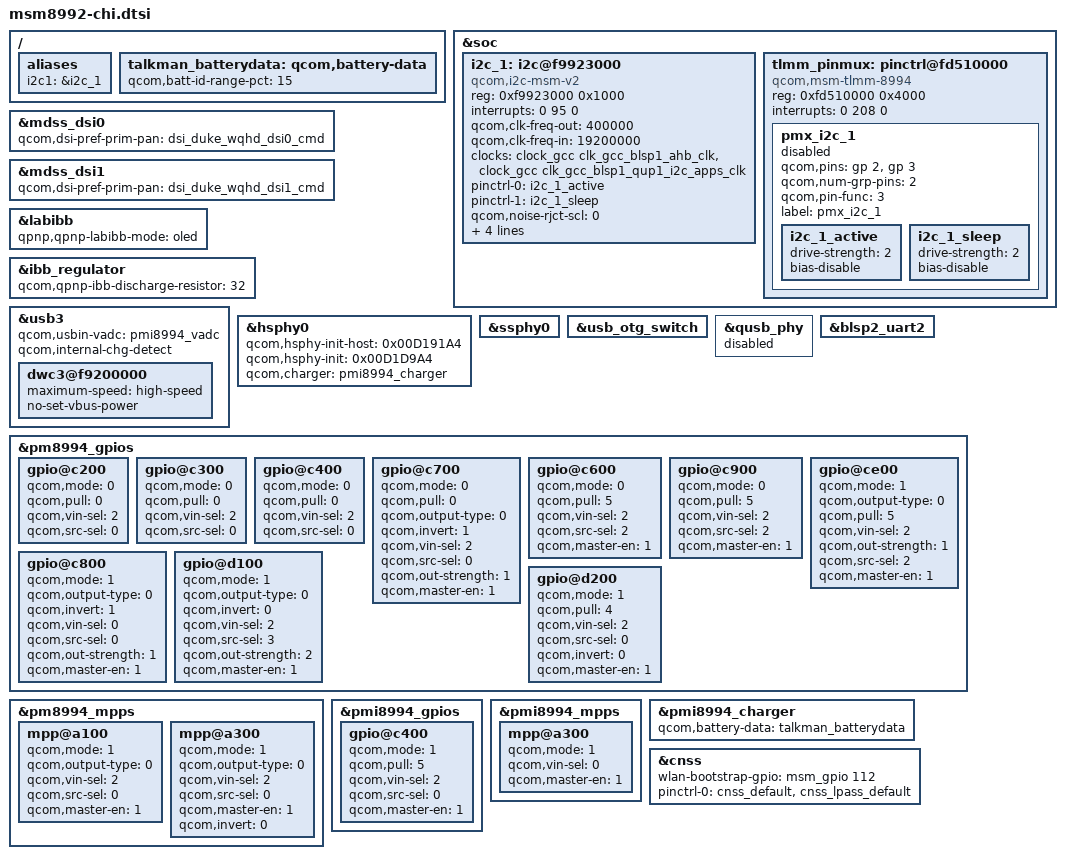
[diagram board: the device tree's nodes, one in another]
/* Copyright (c) 2014-2015, The Linux Foundation. All rights reserved.
 *
 * This program is free software; you can redistribute it and/or modify
 * it under the terms of the GNU General Public License version 2 and
 * only version 2 as published by the Free Software Foundation.
 *
 * This program is distributed in the hope that it will be useful,
 * but WITHOUT ANY WARRANTY; without even the implied warranty of
 * MERCHANTABILITY or FITNESS FOR A PARTICULAR PURPOSE.  See the
 * GNU General Public License for more details.
 */

 #include "../qcom/msm8992-pinctrl.dtsi"
 #include "common/pinctrl.dtsi"
 #include "../qcom/msm8992-camera-sensor-mtp.dtsi"
 #include "common/regulator.dtsi"
 #include "common/connectivity.dtsi"
 #include "common/sdhc.dtsi"
 #include "common/haptics.dtsi"
 #include "common/touch.dtsi"
 #include "common/silabs.dtsi"
 #include "common/sidekeys.dtsi"
 #include "common/audio.dtsi"
 #include "common/adc.dtsi"
 #include "common/charger.dtsi"
 #include "common/hdmi.dtsi"
 #include "common/mdss.dtsi"
 #include "common/reserved-memory.dtsi"
 #include "common/nfc.dtsi"
 #include "common/ice40.dtsi"
 
 / {
	 aliases {
		 i2c1 = &i2c_1;
	 };
 };
 
 &soc {
		 i2c_1: i2c@f9923000 {
		 compatible = "qcom,i2c-msm-v2";
		 #address-cells = <1>;
		 #size-cells = <0>;
		 reg-names = "qup_phys_addr";
		 reg = <0xf9923000 0x1000>;
		 interrupt-names = "qup_irq";
		 interrupts = <0 95 0>;
		 qcom,clk-freq-out = <400000>;
		 qcom,clk-freq-in  = <19200000>;
		 clock-names = "iface_clk", "core_clk";
		 clocks = <&clock_gcc clk_gcc_blsp1_ahb_clk>,
			  <&clock_gcc clk_gcc_blsp1_qup1_i2c_apps_clk>;
 
		 pinctrl-names = "i2c_active", "i2c_sleep";
		 pinctrl-0 = <&i2c_1_active>;
		 pinctrl-1 = <&i2c_1_sleep>;
		 qcom,noise-rjct-scl = <0>;
		 qcom,noise-rjct-sda = <0>;
		 qcom,master-id = <86>;
		 dmas = <&dma_blsp1 10 64 0x20000020 0x20>,
			 <&dma_blsp1 11 32 0x20000020 0x20>;
		 dma-names = "tx", "rx";
 
	 };
 
 
		 tlmm_pinmux: pinctrl@fd510000 {
		 compatible = "qcom,msm-tlmm-8994", "qcom,msm-tlmm-8974";
		 reg = <0xfd510000 0x4000>;
		 interrupts = <0 208 0>;
 
			 pmx_i2c_1 {
			 qcom,pins = <&gp 2>, <&gp 3>; /* SDA, SCL */
			 qcom,num-grp-pins = <2>;
			 qcom,pin-func = <3>;
			 label = "pmx_i2c_1";
 
			 status = "disabled";
 
			 i2c_1_active: i2c_1_active {
				 drive-strength = <2>;
				 bias-disable;
			 };
 
			 i2c_1_sleep: i2c_1_sleep {
				 drive-strength = <2>;
				 bias-disable;
			 };
		 };
	 };
 
 };
 
 #include "panels/dsi-panel-duke-wqhd-dualdsi-cmd.dtsi"
 
 //Sergej panel has more timout for cmds -- fixing a green line on screen when powering off bug
 //Won't use it though, will just have to adjust the timing later down the line 
&mdss_dsi0 {
	 qcom,dsi-pref-prim-pan = <&dsi_duke_wqhd_dsi0_cmd>;
 };
 
 &mdss_dsi1 {
	 qcom,dsi-pref-prim-pan = <&dsi_duke_wqhd_dsi1_cmd>;
 };
 
 &labibb {
	 status = "ok";
	 qpnp,qpnp-labibb-mode = "oled";
 };
 
 &ibb_regulator {
	 qcom,qpnp-ibb-discharge-resistor = <32>;
 };
 
 &usb3 {
	 status = "ok";
	 qcom,usbin-vadc = <&pmi8994_vadc>;
	 qcom,internal-chg-detect;
 
	 dwc3@f9200000 {
		 maximum-speed = "high-speed";
		 no-set-vbus-power;
	 };
 };
 
 &hsphy0 {
	 status = "ok";
	 qcom,hsphy-init-host = <0x00D191A4>;
	 qcom,hsphy-init = <0x00D1D9A4>;
	 qcom,charger = <&pmi8994_charger>;
 };
 
 &ssphy0 {
	 status = "ok";
 };
 
 &usb_otg_switch {
	 status = "ok";
 };
 &qusb_phy {
	 status = "disabled";
 };
 
 &blsp2_uart2 {
	 status = "ok";
 };
 
 &pm8994_gpios {
	 gpio@c200 { /* GPIO 3 */
		 qcom,mode = <0>;		/* Digital in */
		 qcom,pull = <0>;		/* PULL up 30uA */
		 qcom,vin-sel = <2>;		/* Logical 1 voltage value 1.8v */
		 qcom,src-sel = <0>;		/* Constant */
		 status = "okay";
	 };
 
	 gpio@c300 { /* GPIO 4 */
		 qcom,mode = <0>;		/* Digital in */
		 qcom,pull = <0>;		/* PULL up 30uA */
		 qcom,vin-sel = <2>;		/* Logical 1 voltage value 1.8v */
		 qcom,src-sel = <0>;		/* Constant */
		 status = "okay";
	 };
 
	 gpio@c400 { /* GPIO 5 */
		 qcom,mode = <0>;		/* Digital in */
		 qcom,pull = <0>;		/* PULL up 30uA */
		 qcom,vin-sel = <2>;		/* Logical 1 voltage value 1.8v */
		 qcom,src-sel = <0>;		/* Constant */
		 status = "okay";
	 };
 
	 gpio@c700 { /* GPIO 8 */
		 qcom,mode = <0>;                /* Digital in */
		 qcom,pull = <0>;                /* PULL up 30uA */
		 qcom,output-type = <0>;         /* CMOS logic */
		 qcom,invert = <1>;              /* Output high */
		 qcom,vin-sel = <2>;             /* Logical 1 voltage value 1.8v */
		 qcom,src-sel = <0>;             /* Constant */
		 qcom,out-strength = <1>;        /* Low drive strength */
		 qcom,master-en = <1>;           /* Enable GPIO */
		 status = "okay";
	 };
 
	 gpio@c600 { /* GPIO 7 */
		 /* NFC pwr request */
		 qcom,mode = <0>;		/* QPNP_PIN_MODE_DIG_IN */
		 qcom,pull = <5>;		/* QPNP_PIN_PULL_NO */
		 qcom,vin-sel = <2>;		/* QPNP_PIN_VIN2 */
		 qcom,src-sel = <2>;		/* QPNP_PIN_SEL_FUNC_1 */
		 qcom,master-en = <1>;
		 status = "okay";
	 };
 
	 gpio@c900 { /* GPIO 10 */
		 /* NFC clk request */
		 qcom,mode = <0>;		/* QPNP_PIN_MODE_DIG_IN */
		 qcom,pull = <5>;		/* QPNP_PIN_PULL_NO */
		 qcom,vin-sel = <2>;		/* QPNP_PIN_VIN2 */
		 qcom,src-sel = <2>;		/* QPNP_PIN_SEL_FUNC_1 */
		 qcom,master-en = <1>;
		 status = "okay";
	 };
 
	 gpio@ce00 { /* GPIO 15 */
		 qcom,mode = <1>;
		 qcom,output-type = <0>;
		 qcom,pull = <5>;
		 qcom,vin-sel = <2>;
		 qcom,out-strength = <1>;
		 qcom,src-sel = <2>;
		 qcom,master-en = <1>;
		 status = "okay";
	 };
 
	 gpio@c800 { /* GPIO 9 */
		 qcom,mode = <1>;		/* Digital output */
		 qcom,output-type = <0>;		/* CMOS logic */
		 qcom,invert = <1>;		/* Output high */
		 qcom,vin-sel = <0>;		/* VPH_PWR */
		 qcom,src-sel = <0>;		/* Constant */
		 qcom,out-strength = <1>;	/* High drive strength */
		 qcom,master-en = <1>;		/* Enable GPIO */
		 status = "okay";
	 };
 
	 gpio@d100 { /* GPIO 18 */
		 qcom,mode = <1>;		/* Digital output */
		 qcom,output-type = <0>;		/* CMOS logic */
		 qcom,invert = <0>;		/* Output low initially */
		 qcom,vin-sel = <2>;		/* VIN 2 */
		 qcom,src-sel = <3>;		/* Function 2 */
		 qcom,out-strength = <2>;	/* Medium */
		 qcom,master-en = <1>;		/* Enable GPIO */
		 status = "okay";
	 };
 
	 gpio@d200 { /* GPIO 19 */
		 qcom,mode = <1>;		/* Digital output*/
		 qcom,pull = <4>;		/* Pulldown 10uA */
		 qcom,vin-sel = <2>;		/* VIN2 */
		 qcom,src-sel = <0>;		/* GPIO */
		 qcom,invert = <0>;		/* Invert */
		 qcom,master-en = <1>;		/* Enable GPIO */
		 status = "okay";
	 };
 };
 
 &pm8994_mpps {
	 mpp@a100 { /* MPP 2 */
		 qcom,mode = <1>;		/* Digital output */
		 qcom,output-type = <0>;		/* CMOS logic */
		 qcom,vin-sel = <2>;		/* S4 1.8V */
		 qcom,src-sel = <0>;		/* Constant */
		 qcom,master-en = <1>;		/* Enable GPIO */
		 status = "okay";
	 };
 
	 mpp@a300 { /* MPP 4 */
		 /* HDMI_5v_vreg regulator enable */
		 qcom,mode = <1>;		/* Digital output */
		 qcom,output-type = <0>;		/* CMOS logic */
		 qcom,vin-sel = <2>;		/* S4 1.8V */
		 qcom,src-sel = <0>;		/* Constant */
		 qcom,master-en = <1>;		/* Enable GPIO */
		 qcom,invert = <0>;
		 status = "okay";
	 };
 };
 
 
 &pmi8994_gpios {
	 gpio@c400 {	/* GPIO 5  OTG SWITCH EN */
		 qcom,mode = <1>;	/* DIGITAL OUT */
		 qcom,pull = <5>;	/* No Pull */
		 qcom,vin-sel = <2>;	/* 1.8 */
		 qcom,src-sel = <0>;	/* GPIO */
		 qcom,master-en = <1>;	/* ENABLE GPIO */
		 status = "okay";
	 };
 };
 
 &pmi8994_mpps {
	 mpp@a300 { /* MPP 4 */
		 /* WLED FET */
		 qcom,mode = <1>;	/* DIGITAL OUT */
		 qcom,vin-sel = <0>;	/* VIN0 */
		 qcom,master-en = <1>;
		 status = "okay";
	 };
 };
 
 /{
	 talkman_batterydata: qcom,battery-data {
		 qcom,batt-id-range-pct = <15>;
		 #include "microsoft_bvt5e_3000mah.dtsi"
	 };
 };
 
 &pmi8994_charger {
	 qcom,battery-data = <&talkman_batterydata>;
 };
 
 &cnss {
 	wlan-bootstrap-gpio = <&msm_gpio 112 0>;
 	pinctrl-names = "default";
 	pinctrl-0 = <&cnss_default &cnss_lpass_default>;
 };
